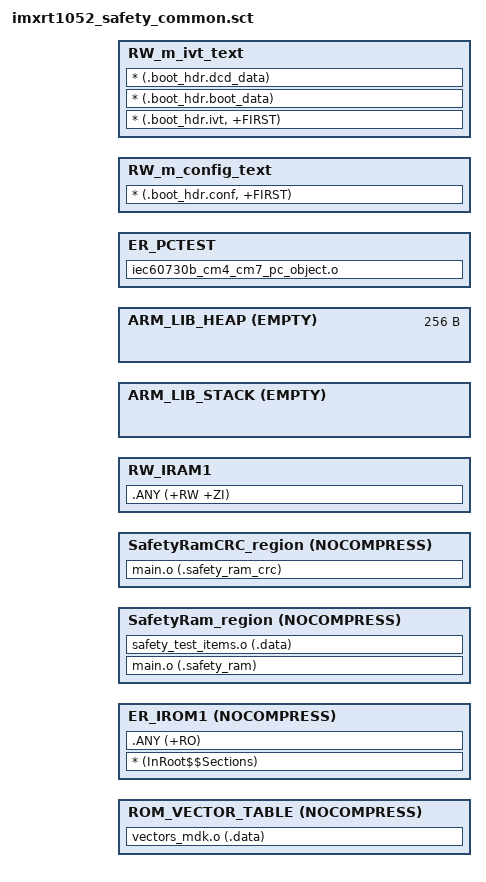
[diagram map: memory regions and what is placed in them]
#! armcc -E -I .\startup

/**********************************************************************************/
/****************************        MEMORY MAP        ****************************/
/**********************************************************************************/

/********************        FLASH        ********************/
//     __________________
//    |                  | --> 0x60000000 - m_boot_hdr_conf_start
//    |  XIP boot header |
//    |__________________|
//    |                  | --> 0x60002000 - ROM_interrupts_start
//    |       IVT        |
//    |__________________|
//    |                  | --> 0x60002400 - __FlashCRC_start__
//    |       CRC        |
//    |__________________|
//    |                  | --> 0x60002410 - __PC_test_start__
//    |   PC_object.o    |
//    |__________________|
//    |                  | --> 0x60002430 - ROM_start
//    |     readonly     |
//    |   .textrw_init   |
//    |   .data_init     |
//    |__________________| --> 0x63FFFFFF - ROM_end
//
//
/********************        SRAM        ********************/
//     __________________
//    |                  | --> 0x00000000 - SRAM_ITC_start
//    |//// NOT USED ////|
//    |__________________| --> 0x0001FFFF - SRAM_ITC_end 
//    |                  |
//    |//// RESERVED ////|
//    |__________________|
//    |                  | --> 0x20000000 - SRAM_DTC_start
//    |     RW (.data)   | --> copying in startup_iar.c
//    |     ZI (.bss)    | --> copying in startup_iar.c
//    | SAFETY_RAM_BLOCK | 
//    |__________________| --> SRAM_DTC_end_edited
//    |                  | --> m_stack_test_p_1
//    |                  |
//    |__________________| --> m_stack_test_p_2
//    |                  |
//    |                  |
//    |      STACK       |
//    |                  |
//    |__________________| --> __BOOT_STACK_ADDRESS
//    |                  | --> m_stack_test_p_3
//    |                  |
//    |__________________| --> m_stack_test_p_4
//    |__________________| --> m_safety_error_code
//    |__________________| --> m_pc_test_flag
//    |                  | --> m_wd_test_backup
//    |__________________|
//    |                  |
//    |                  | --> m_ram_test_backup
//    |__________________|
//    |__________________| --> 0x2001FFFF - SRAM_DTC_end
//    |                  |
//    |//// RESERVED ////|
//    |__________________|
//    |                  | --> 0x20200000 - SRAM_OC_start
//    |//// NOT USED ////|
//    |__________________| --> 0x2023FFFF - SRAM_OC_end
//
//
/********************        SDRAM        ********************/
//     __________________
//    |                  | --> 0x80000000 - SDRAM_start
//    |//// NOT USED ////|
//    |__________________|
//    |__________________| --> 0x81FFDBEC - PC test pattern (defined in safety_config.h as PC_TEST_PATTERN_RT)
//    |                  |
//    |//// NOT USED ////|
//    |__________________| --> 0x81FFFFFF - SDRAM_end
//
//

; *************************************************************
; *** Scatter-Loading Description File                      ***
; *************************************************************
#include "linker_config.h"

/************ IVT ************/
LR_IROM1_IVT ROM_interrupts_start __vector_table_size__ {   ; load region size_region
	ROM_VECTOR_TABLE ROM_interrupts_start NOCOMPRESS __vector_table_size__ { ; load address = execution address
	    vectors_mdk.o (.data)
	}
}

/************ RO, RW, ZI, safety ram, stack ************/
LR_IROM1 ROM_start ROM_end - ROM_start + 1 {
	ER_IROM1 ROM_start NOCOMPRESS ROM_end - ROM_start + 1 { ; load address = execution address
		* (InRoot$$Sections)
		.ANY (+RO)
	}

	SafetyRam_region m_safety_ram_start NOCOMPRESS SAFETY_RAM_SIZE{
		main.o (.safety_ram)
		safety_test_items.o (.data)
	}
	
	SafetyRamCRC_region m_safety_ram_crc_start NOCOMPRESS SAFETY_RAM_CRC_SIZE{
		main.o (.safety_ram_crc)
	}

	RW_IRAM1 SRAM_DTC_start SRAM_DTC_end - SRAM_DTC_start + 1  {  ; RW data
		.ANY (+RW +ZI)
	}

	ARM_LIB_STACK __BOOT_STACK_ADDRESS EMPTY -__size_cstack__{ ; Stack region growing down
	}
	
	ARM_LIB_HEAP SRAM_ITC_start EMPTY 0x100 { ; Heap region growing up
    }
}

/************ PC test object ************/
LR_PC_OBJECT __PC_test_start__ __PC_test_end__ - __PC_test_start__ + 1 {
	ER_PCTEST __PC_test_start__ __PC_test_end__ - __PC_test_start__ + 1 {
		iec60730b_cm4_cm7_pc_object.o 
	}
}

/************ XIP boot header ************/
LR_m_rom_config m_flash_config_start m_flash_config_size {   ; load region size_region
	RW_m_config_text m_flash_config_start m_flash_config_size { ; load address = execution address
	* (.boot_hdr.conf, +FIRST)
	}
}
LR_m_rom_ivt m_ivt_start m_ivt_size {   ; load region size_region
	RW_m_ivt_text m_ivt_start m_ivt_size { ; load address = execution address
	* (.boot_hdr.ivt, +FIRST)
	* (.boot_hdr.boot_data)
	* (.boot_hdr.dcd_data)
	}
}
